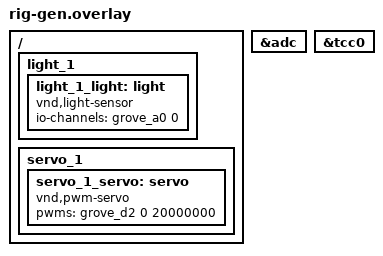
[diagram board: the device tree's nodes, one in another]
/* generated by rigc — do not edit; the rig file is the source of truth (R3)
 * rig: lotus_pwm  board: seeeduino_lotus/samd21g18a/rig
 */

/ {
	light_1 {
		light_1_light: light {
			compatible = "vnd,light-sensor";
			io-channels = <&grove_a0 0>;	/* SIG0 */
			status = "okay";
		};
	};
	servo_1 {
		servo_1_servo: servo {
			compatible = "vnd,pwm-servo";
			pwms = <&grove_d2 0 20000000>;	/* SIG0 */
			status = "okay";
		};
	};
};

/* PWM/ADC: enable the resolved controllers; the pin-mux (pinctrl)
 * for each muxed pin is board-provided and must be applied —
 * stubbed here, see the config sheet. */
&adc { status = "okay"; };
&tcc0 { status = "okay"; };
